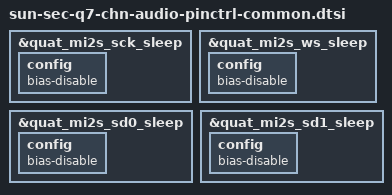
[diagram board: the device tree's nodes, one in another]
// SPDX-License-Identifier: BSD-3-Clause
/*
 * Copyright (c) 2023-2024 Qualcomm Innovation Center, Inc. All rights reserved.
 */
&quat_mi2s_sck_sleep {
	config {
		/delete-property/ bias-pull-down;
		bias-disable;
	};
};

&quat_mi2s_ws_sleep {
	config {
		/delete-property/ bias-pull-down;
		bias-disable;
	};
};

&quat_mi2s_sd0_sleep {
	config {
		/delete-property/ bias-pull-down;
		bias-disable;
	};
};

&quat_mi2s_sd1_sleep {
	config {
		/delete-property/ bias-pull-down;
		bias-disable;
	};
};

